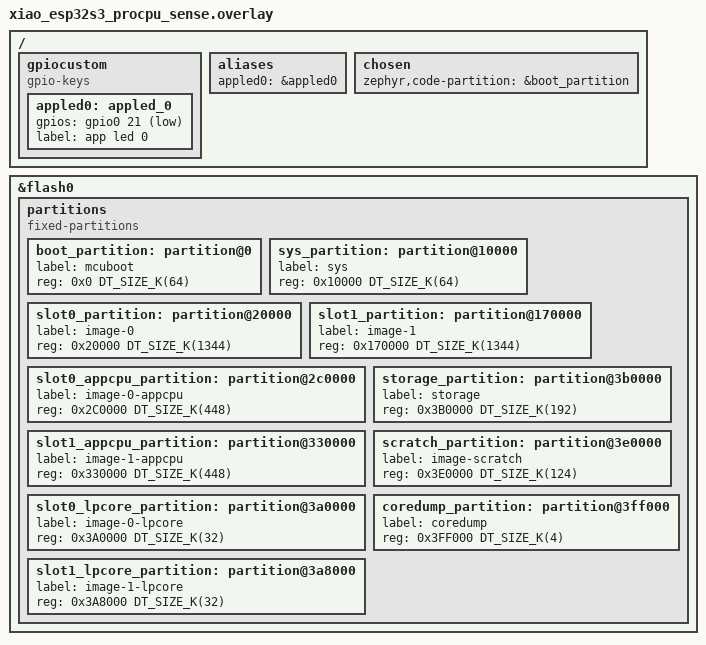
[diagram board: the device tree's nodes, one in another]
/delete-node/ &boot_partition;
/delete-node/ &sys_partition;
/delete-node/ &slot0_partition;
/delete-node/ &slot1_partition;
/ {
    gpiocustom {
        compatible = "gpio-keys";
        appled0: appled_0 {
            gpios = <&gpio0 21 GPIO_ACTIVE_LOW>;
            label = "app led 0";
        };
    };

    aliases {
        appled0 = &appled0;
    };

	chosen {
		zephyr,code-partition = &boot_partition;
	};
};

&flash0 {
	partitions {
		compatible = "fixed-partitions";
		#address-cells = <1>;
		#size-cells = <1>;

		boot_partition: partition@0 {
			label = "mcuboot";
			reg = <0x0 DT_SIZE_K(64)>;
		};

		sys_partition: partition@10000 {
			label = "sys";
			reg = <0x10000 DT_SIZE_K(64)>;
		};

		slot0_partition: partition@20000 {
			label = "image-0";
			reg = <0x20000 DT_SIZE_K(1344)>;
		};

		slot1_partition: partition@170000 {
			label = "image-1";
			reg = <0x170000 DT_SIZE_K(1344)>;
		};

		slot0_appcpu_partition: partition@2c0000 {
			label = "image-0-appcpu";
			reg = <0x2C0000 DT_SIZE_K(448)>;
		};

		slot1_appcpu_partition: partition@330000 {
			label = "image-1-appcpu";
			reg = <0x330000 DT_SIZE_K(448)>;
		};

		slot0_lpcore_partition: partition@3a0000 {
			label = "image-0-lpcore";
			reg = <0x3A0000 DT_SIZE_K(32)>;
		};

		slot1_lpcore_partition: partition@3a8000 {
			label = "image-1-lpcore";
			reg = <0x3A8000 DT_SIZE_K(32)>;
		};

		storage_partition: partition@3b0000 {
			label = "storage";
			reg = <0x3B0000 DT_SIZE_K(192)>;
		};

		scratch_partition: partition@3e0000 {
			label = "image-scratch";
			reg = <0x3E0000 DT_SIZE_K(124)>;
		};

		coredump_partition: partition@3ff000 {
			label = "coredump";
			reg = <0x3FF000 DT_SIZE_K(4)>;
		};
	};
};
